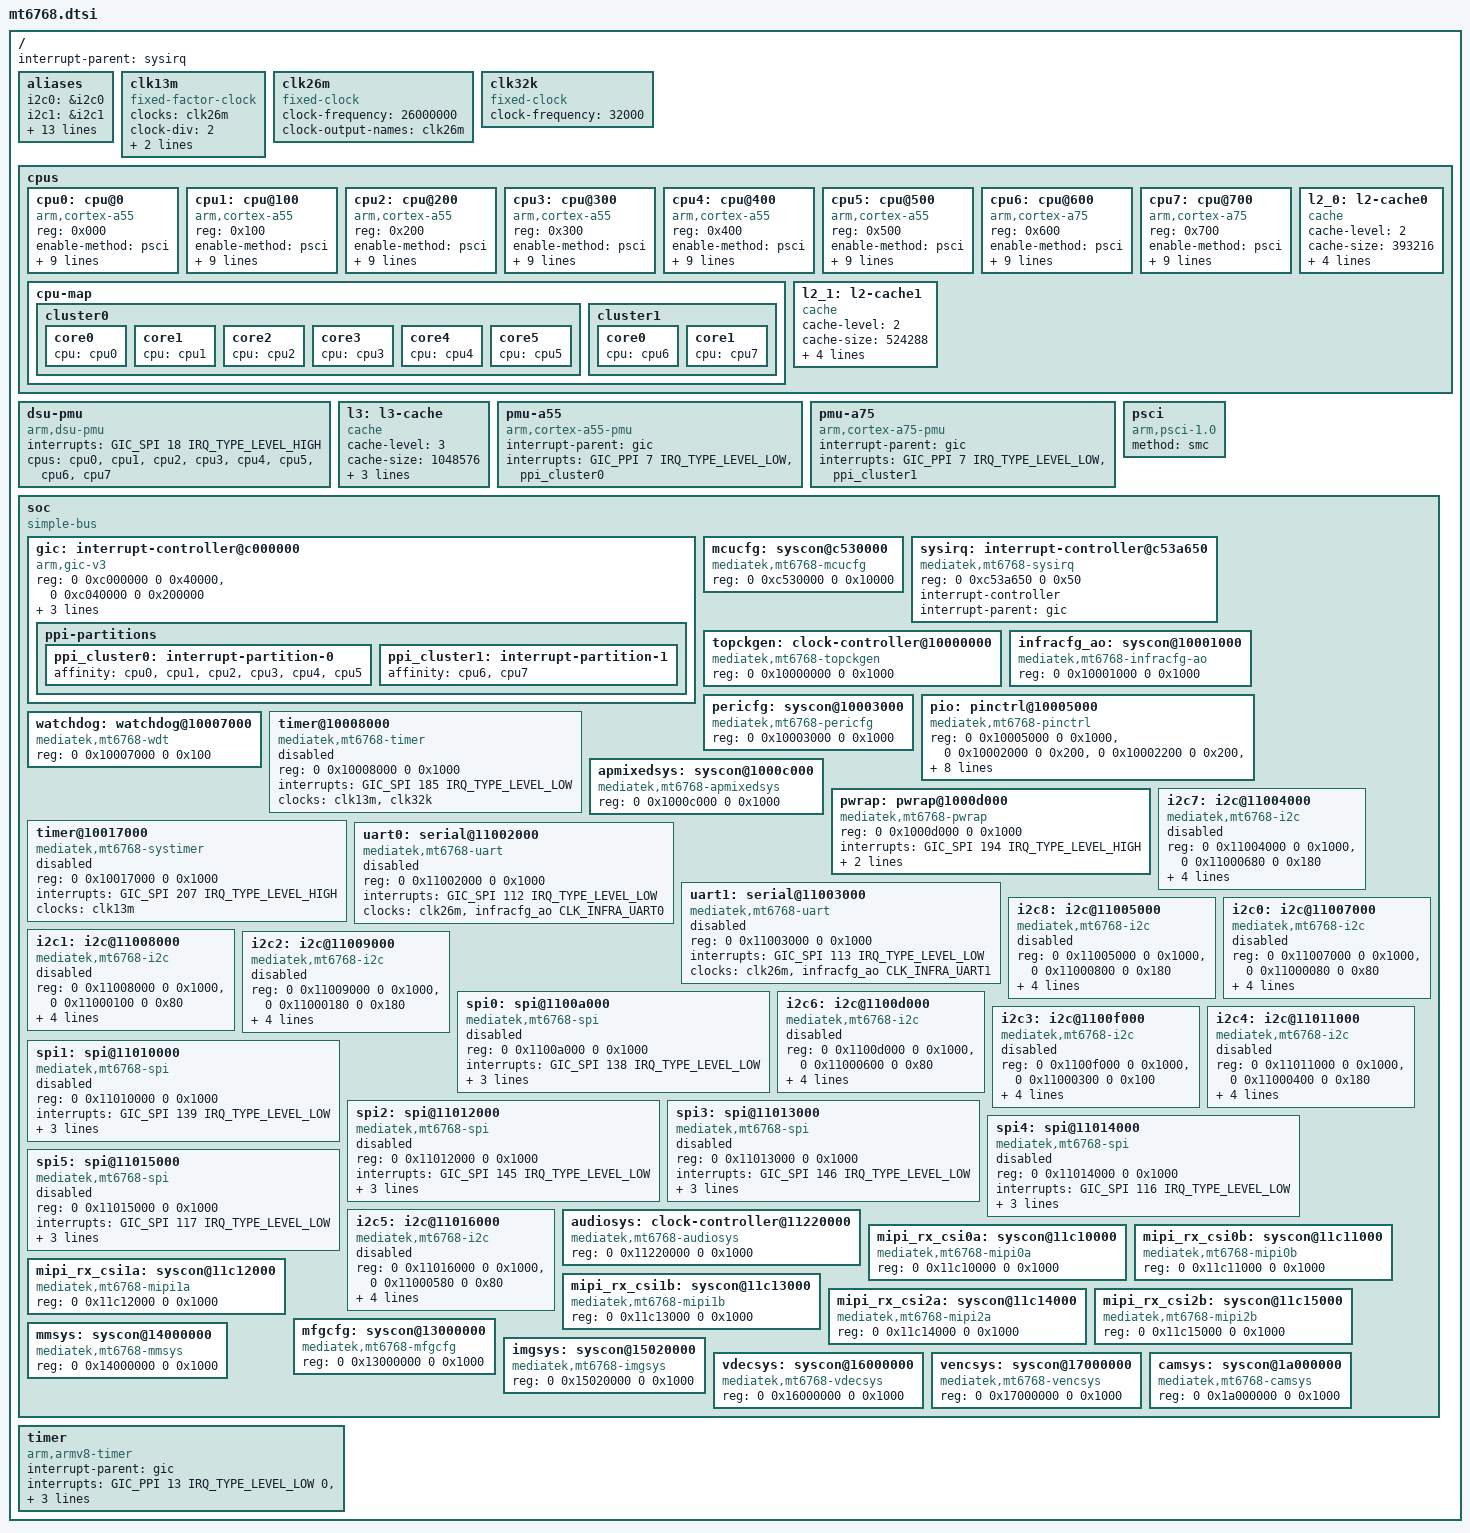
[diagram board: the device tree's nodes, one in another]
// SPDX-License-Identifier: GPL-2.0+
/*
 * Copyright (c) 2025-2026 Roman Vivchar <rva333@protonmail.com>
 */

#include <dt-bindings/interrupt-controller/arm-gic.h>
#include <dt-bindings/interrupt-controller/irq.h>
#include <dt-bindings/clock/mediatek,mt6768-clock.h>
#include <dt-bindings/pinctrl/mediatek,mt6768-pinfunc.h>
#include <dt-bindings/reset/mediatek,mt6768-resets.h>

/ {
	interrupt-parent = <&sysirq>;
	#address-cells = <2>;
	#size-cells = <2>;

	aliases {
		i2c0 = &i2c0;
		i2c1 = &i2c1;
		i2c2 = &i2c2;
		i2c3 = &i2c3;
		i2c4 = &i2c4;
		i2c5 = &i2c5;
		i2c6 = &i2c6;
		i2c7 = &i2c7;
		i2c8 = &i2c8;
		spi0 = &spi0;
		spi1 = &spi1;
		spi2 = &spi2;
		spi3 = &spi3;
		spi4 = &spi4;
		spi5 = &spi5;
	};

	clk13m: clk13m {
		compatible = "fixed-factor-clock";
		#clock-cells = <0>;
		clocks = <&clk26m>;
		clock-div = <2>;
		clock-mult = <1>;
		clock-output-names = "clk13m";
	};

	clk26m: clk26m {
		compatible = "fixed-clock";
		#clock-cells = <0>;
		clock-frequency = <26000000>;
		clock-output-names = "clk26m";
	};

	clk32k: clk32k {
		compatible = "fixed-clock";
		#clock-cells = <0>;
		clock-frequency = <32000>;
	};

	cpus {
		#address-cells = <1>;
		#size-cells = <0>;

		cpu0: cpu@0 {
			device_type = "cpu";
			compatible = "arm,cortex-a55";
			reg = <0x000>;
			enable-method = "psci";
			dynamic-power-coefficient = <85>;
			capacity-dmips-mhz = <495>;
			i-cache-size = <32768>;
			i-cache-line-size = <64>;
			i-cache-sets = <256>;
			d-cache-size = <32768>;
			d-cache-line-size = <64>;
			d-cache-sets = <128>;
			next-level-cache = <&l2_0>;
			#cooling-cells = <2>;
		};

		cpu1: cpu@100 {
			device_type = "cpu";
			compatible = "arm,cortex-a55";
			reg = <0x100>;
			enable-method = "psci";
			dynamic-power-coefficient = <85>;
			capacity-dmips-mhz = <495>;
			i-cache-size = <32768>;
			i-cache-line-size = <64>;
			i-cache-sets = <256>;
			d-cache-size = <32768>;
			d-cache-line-size = <64>;
			d-cache-sets = <128>;
			next-level-cache = <&l2_0>;
			#cooling-cells = <2>;
		};

		cpu2: cpu@200 {
			device_type = "cpu";
			compatible = "arm,cortex-a55";
			reg = <0x200>;
			enable-method = "psci";
			dynamic-power-coefficient = <85>;
			capacity-dmips-mhz = <495>;
			i-cache-size = <32768>;
			i-cache-line-size = <64>;
			i-cache-sets = <256>;
			d-cache-size = <32768>;
			d-cache-line-size = <64>;
			d-cache-sets = <128>;
			next-level-cache = <&l2_0>;
			#cooling-cells = <2>;
		};

		cpu3: cpu@300 {
			device_type = "cpu";
			compatible = "arm,cortex-a55";
			reg = <0x300>;
			enable-method = "psci";
			dynamic-power-coefficient = <85>;
			capacity-dmips-mhz = <495>;
			i-cache-size = <32768>;
			i-cache-line-size = <64>;
			i-cache-sets = <256>;
			d-cache-size = <32768>;
			d-cache-line-size = <64>;
			d-cache-sets = <128>;
			next-level-cache = <&l2_0>;
			#cooling-cells = <2>;
		};

		cpu4: cpu@400 {
			device_type = "cpu";
			compatible = "arm,cortex-a55";
			reg = <0x400>;
			enable-method = "psci";
			dynamic-power-coefficient = <85>;
			capacity-dmips-mhz = <495>;
			i-cache-size = <32768>;
			i-cache-line-size = <64>;
			i-cache-sets = <256>;
			d-cache-size = <32768>;
			d-cache-line-size = <64>;
			d-cache-sets = <128>;
			next-level-cache = <&l2_0>;
			#cooling-cells = <2>;
		};

		cpu5: cpu@500 {
			device_type = "cpu";
			compatible = "arm,cortex-a55";
			reg = <0x500>;
			enable-method = "psci";
			dynamic-power-coefficient = <85>;
			capacity-dmips-mhz = <495>;
			i-cache-size = <32768>;
			i-cache-line-size = <64>;
			i-cache-sets = <256>;
			d-cache-size = <32768>;
			d-cache-line-size = <64>;
			d-cache-sets = <128>;
			next-level-cache = <&l2_0>;
			#cooling-cells = <2>;
		};

		cpu6: cpu@600 {
			device_type = "cpu";
			compatible = "arm,cortex-a75";
			reg = <0x600>;
			enable-method = "psci";
			dynamic-power-coefficient = <275>;
			capacity-dmips-mhz = <1024>;
			i-cache-size = <65536>;
			i-cache-line-size = <64>;
			i-cache-sets = <256>;
			d-cache-size = <65536>;
			d-cache-line-size = <64>;
			d-cache-sets = <256>;
			next-level-cache = <&l2_1>;
			#cooling-cells = <2>;
		};

		cpu7: cpu@700 {
			device_type = "cpu";
			compatible = "arm,cortex-a75";
			reg = <0x700>;
			enable-method = "psci";
			dynamic-power-coefficient = <275>;
			capacity-dmips-mhz = <1024>;
			i-cache-size = <65536>;
			i-cache-line-size = <64>;
			i-cache-sets = <256>;
			d-cache-size = <65536>;
			d-cache-line-size = <64>;
			d-cache-sets = <256>;
			next-level-cache = <&l2_1>;
			#cooling-cells = <2>;
		};

		cpu-map {
			cluster0 {
				core0 {
					cpu = <&cpu0>;
				};

				core1 {
					cpu = <&cpu1>;
				};

				core2 {
					cpu = <&cpu2>;
				};

				core3 {
					cpu = <&cpu3>;
				};

				core4 {
					cpu = <&cpu4>;
				};

				core5 {
					cpu = <&cpu5>;
				};
			};

			cluster1 {
				core0 {
					cpu = <&cpu6>;
				};

				core1 {
					cpu = <&cpu7>;
				};
			};
		};

		l2_0: l2-cache0 {
			compatible = "cache";
			cache-level = <2>;
			cache-size = <393216>; // 64K x 6
			cache-line-size = <64>;
			cache-sets = <512>; // I guess
			next-level-cache = <&l3>;
			cache-unified;
		};

		l2_1: l2-cache1 {
			compatible = "cache";
			cache-level = <2>;
			cache-size = <524288>; // 256K x 2
			cache-line-size = <64>;
			cache-sets = <512>;
			next-level-cache = <&l3>;
			cache-unified;
		};
	};

	dsu-pmu {
		compatible = "arm,dsu-pmu";
		interrupts = <GIC_SPI 18 IRQ_TYPE_LEVEL_HIGH>;
		cpus = <&cpu0>, <&cpu1>, <&cpu2>, <&cpu3>,
		       <&cpu4>, <&cpu5>, <&cpu6>, <&cpu7>;
	};

	l3: l3-cache {
		compatible = "cache";
		cache-level = <3>;
		cache-size = <1048576>;
		cache-line-size = <64>;
		cache-sets = <1024>;
		cache-unified;
	};

	pmu-a55 {
		compatible = "arm,cortex-a55-pmu";
		interrupt-parent = <&gic>;
		interrupts = <GIC_PPI 7 IRQ_TYPE_LEVEL_LOW &ppi_cluster0>;
	};

	pmu-a75 {
		compatible = "arm,cortex-a75-pmu";
		interrupt-parent = <&gic>;
		interrupts = <GIC_PPI 7 IRQ_TYPE_LEVEL_LOW &ppi_cluster1>;
	};

	psci {
		compatible = "arm,psci-1.0";
		method = "smc";
	};

	soc {
		compatible = "simple-bus";
		ranges;
		#address-cells = <2>;
		#size-cells = <2>;

		gic: interrupt-controller@c000000 {
			compatible = "arm,gic-v3";
			reg = <0 0xc000000 0 0x40000>,
			      <0 0xc040000 0 0x200000>;
			#interrupt-cells = <4>;
			interrupt-parent = <&gic>;
			interrupt-controller;

			interrupts = <GIC_PPI 9 IRQ_TYPE_LEVEL_HIGH 0>;

			ppi-partitions {
				ppi_cluster0: interrupt-partition-0 {
					affinity = <&cpu0 &cpu1 &cpu2 &cpu3 &cpu4 &cpu5>;
				};

				ppi_cluster1: interrupt-partition-1 {
					affinity = <&cpu6 &cpu7>;
				};
			};
		};

		mcucfg: syscon@c530000 {
			compatible = "mediatek,mt6768-mcucfg", "syscon";
			reg = <0 0xc530000 0 0x10000>;
			#clock-cells = <1>;
		};

		sysirq: interrupt-controller@c53a650 {
			compatible = "mediatek,mt6768-sysirq", "mediatek,mt6577-sysirq";
			reg = <0 0xc53a650 0 0x50>;
			interrupt-controller;
			#interrupt-cells = <3>;
			interrupt-parent = <&gic>;
		};

		topckgen: clock-controller@10000000 {
			compatible = "mediatek,mt6768-topckgen", "syscon";
			reg = <0 0x10000000 0 0x1000>;
			#clock-cells = <1>;
		};

		infracfg_ao: syscon@10001000 {
			compatible = "mediatek,mt6768-infracfg-ao", "syscon";
			reg = <0 0x10001000 0 0x1000>;
			#clock-cells = <1>;
			#reset-cells = <1>;
		};

		pericfg: syscon@10003000 {
			compatible = "mediatek,mt6768-pericfg", "syscon";
			reg = <0 0x10003000 0 0x1000>;
		};

		pio: pinctrl@10005000 {
			compatible = "mediatek,mt6768-pinctrl";
			reg = <0 0x10005000 0 0x1000>,
			      <0 0x10002000 0 0x200>,
			      <0 0x10002200 0 0x200>,
			      <0 0x10002400 0 0x200>,
			      <0 0x10002600 0 0x200>,
			      <0 0x10002800 0 0x200>,
			      <0 0x10002a00 0 0x200>,
			      <0 0x10002c00 0 0x200>,
			      <0 0x10002e00 0 0x200>,
			      <0 0x1000b000 0 0x1000>;
			reg-names = "gpio", "iocfg_lt", "iocfg_lm", "iocfg_lb",
				    "iocfg_bl", "iocfg_rm", "iocfg_rb", "iocfg_rt",
				    "iocfg_tl", "eint";
			gpio-controller;
			#gpio-cells = <2>;
			gpio-ranges = <&pio 0 0 187>;
			interrupt-controller;
			interrupts = <GIC_SPI 186 IRQ_TYPE_LEVEL_HIGH>;
			#interrupt-cells = <2>;
		};

		watchdog: watchdog@10007000 {
			compatible = "mediatek,mt6768-wdt";
			reg = <0 0x10007000 0 0x100>;
			#reset-cells = <1>;
		};

		timer@10008000 {
			compatible = "mediatek,mt6768-timer",
				     "mediatek,mt6577-timer";
			reg = <0 0x10008000 0 0x1000>;
			interrupts = <GIC_SPI 185 IRQ_TYPE_LEVEL_LOW>;
			clocks = <&clk13m>, <&clk32k>;

			status = "disabled";
		};

		apmixedsys: syscon@1000c000 {
			compatible = "mediatek,mt6768-apmixedsys", "syscon";
			reg = <0 0x1000c000 0 0x1000>;
			#clock-cells = <1>;
		};

		pwrap: pwrap@1000d000 {
			compatible = "mediatek,mt6768-pwrap";
			reg = <0 0x1000d000 0 0x1000>;
			reg-names = "pwrap";
			interrupts = <GIC_SPI 194 IRQ_TYPE_LEVEL_HIGH>;
			clocks = <&infracfg_ao CLK_INFRA_PMIC_AP>,
				 <&infracfg_ao CLK_INFRA_PMIC_TMR>;
			clock-names = "spi", "wrap";
		};

		timer@10017000 {
			compatible = "mediatek,mt6768-systimer",
				     "mediatek,mt6765-timer";
			reg = <0 0x10017000 0 0x1000>;
			interrupts = <GIC_SPI 207 IRQ_TYPE_LEVEL_HIGH>;
			clocks = <&clk13m>;

			status = "disabled";
		};

		uart0: serial@11002000 {
			compatible = "mediatek,mt6768-uart", "mediatek,mt6577-uart";
			reg = <0 0x11002000 0 0x1000>;
			interrupts = <GIC_SPI 112 IRQ_TYPE_LEVEL_LOW>;
			clocks = <&clk26m>, <&infracfg_ao CLK_INFRA_UART0>;
			clock-names = "baud", "bus";

			status = "disabled";
		};

		uart1: serial@11003000 {
			compatible = "mediatek,mt6768-uart", "mediatek,mt6577-uart";
			reg = <0 0x11003000 0 0x1000>;
			interrupts = <GIC_SPI 113 IRQ_TYPE_LEVEL_LOW>;
			clocks = <&clk26m>, <&infracfg_ao CLK_INFRA_UART1>;
			clock-names = "baud", "bus";

			status = "disabled";
		};

		i2c7: i2c@11004000 {
			compatible = "mediatek,mt6768-i2c";
			reg = <0 0x11004000 0 0x1000>,
			      <0 0x11000680 0 0x180>;
			interrupts = <GIC_SPI 110 IRQ_TYPE_LEVEL_LOW>;
			clocks = <&infracfg_ao CLK_INFRA_I2C_AP>,
				 <&infracfg_ao CLK_INFRA_AP_DMA>;
			clock-names = "main", "dma";
			clock-div = <1>;
			#address-cells = <1>;
			#size-cells = <0>;

			status = "disabled";
		};

		i2c8: i2c@11005000 {
			compatible = "mediatek,mt6768-i2c";
			reg = <0 0x11005000 0 0x1000>,
			      <0 0x11000800 0 0x180>;
			interrupts = <GIC_SPI 111 IRQ_TYPE_LEVEL_LOW>;
			clocks = <&infracfg_ao CLK_INFRA_I2C_AP>,
				 <&infracfg_ao CLK_INFRA_AP_DMA>;
			clock-names = "main", "dma";
			clock-div = <1>;
			#address-cells = <1>;
			#size-cells = <0>;

			status = "disabled";
		};

		i2c0: i2c@11007000 {
			compatible = "mediatek,mt6768-i2c";
			reg = <0 0x11007000 0 0x1000>,
			      <0 0x11000080 0 0x80>;
			interrupts = <GIC_SPI 105 IRQ_TYPE_LEVEL_LOW>;
			clocks = <&infracfg_ao CLK_INFRA_I2C_AP>,
				 <&infracfg_ao CLK_INFRA_AP_DMA>;
			clock-names = "main", "dma";
			clock-div = <1>;
			#address-cells = <1>;
			#size-cells = <0>;

			status = "disabled";
		};

		i2c1: i2c@11008000 {
			compatible = "mediatek,mt6768-i2c";
			reg = <0 0x11008000 0 0x1000>,
			      <0 0x11000100 0 0x80>;
			interrupts = <GIC_SPI 106 IRQ_TYPE_LEVEL_LOW>;
			clocks = <&infracfg_ao CLK_INFRA_I2C_AP>,
				 <&infracfg_ao CLK_INFRA_AP_DMA>;
			clock-names = "main", "dma";
			clock-div = <1>;
			#address-cells = <1>;
			#size-cells = <0>;

			status = "disabled";
		};

		i2c2: i2c@11009000 {
			compatible = "mediatek,mt6768-i2c";
			reg = <0 0x11009000 0 0x1000>,
			      <0 0x11000180 0 0x180>;
			interrupts = <GIC_SPI 107 IRQ_TYPE_LEVEL_LOW>;
			clocks = <&infracfg_ao CLK_INFRA_I2C_AP>,
				 <&infracfg_ao CLK_INFRA_AP_DMA>;
			clock-names = "main", "dma";
			clock-div = <1>;
			#address-cells = <1>;
			#size-cells = <0>;

			status = "disabled";
		};

		spi0: spi@1100a000 {
			compatible = "mediatek,mt6768-spi", "mediatek,mt6765-spi";
			reg = <0 0x1100a000 0 0x1000>;
			#address-cells = <1>;
			#size-cells = <0>;
			interrupts = <GIC_SPI 138 IRQ_TYPE_LEVEL_LOW>;
			clocks = <&topckgen CLK_TOP_SYSPLL3_D2>,
				 <&topckgen CLK_TOP_SPI_SEL>,
				 <&infracfg_ao CLK_INFRA_SPI0>;
			clock-names = "parent-clk", "sel-clk", "spi-clk";

			status = "disabled";
		};

		i2c6: i2c@1100d000 {
			compatible = "mediatek,mt6768-i2c";
			reg = <0 0x1100d000 0 0x1000>,
			      <0 0x11000600 0 0x80>;
			interrupts = <GIC_SPI 148 IRQ_TYPE_LEVEL_LOW>;
			clocks = <&infracfg_ao CLK_INFRA_I2C_AP>,
				 <&infracfg_ao CLK_INFRA_AP_DMA>;
			clock-names = "main", "dma";
			clock-div = <1>;
			#address-cells = <1>;
			#size-cells = <0>;

			status = "disabled";
		};

		i2c3: i2c@1100f000 {
			compatible = "mediatek,mt6768-i2c";
			reg = <0 0x1100f000 0 0x1000>,
			      <0 0x11000300 0 0x100>;
			interrupts = <GIC_SPI 108 IRQ_TYPE_LEVEL_LOW>;
			clocks = <&infracfg_ao CLK_INFRA_I2C_AP>,
				 <&infracfg_ao CLK_INFRA_AP_DMA>;
			clock-names = "main", "dma";
			clock-div = <1>;
			#address-cells = <1>;
			#size-cells = <0>;

			status = "disabled";
		};

		spi1: spi@11010000 {
			compatible = "mediatek,mt6768-spi", "mediatek,mt6765-spi";
			reg = <0 0x11010000 0 0x1000>;
			#address-cells = <1>;
			#size-cells = <0>;
			interrupts = <GIC_SPI 139 IRQ_TYPE_LEVEL_LOW>;
			clocks = <&topckgen CLK_TOP_SYSPLL3_D2>,
				 <&topckgen CLK_TOP_SPI_SEL>,
				 <&infracfg_ao CLK_INFRA_SPI1>;
			clock-names = "parent-clk", "sel-clk", "spi-clk";

			status = "disabled";
		};

		i2c4: i2c@11011000 {
			compatible = "mediatek,mt6768-i2c";
			reg = <0 0x11011000 0 0x1000>,
			      <0 0x11000400 0 0x180>;
			interrupts = <GIC_SPI 109 IRQ_TYPE_LEVEL_LOW>;
			clocks = <&infracfg_ao CLK_INFRA_I2C_AP>,
				 <&infracfg_ao CLK_INFRA_AP_DMA>;
			clock-names = "main", "dma";
			clock-div = <1>;
			#address-cells = <1>;
			#size-cells = <0>;

			status = "disabled";
		};

		spi2: spi@11012000 {
			compatible = "mediatek,mt6768-spi", "mediatek,mt6765-spi";
			reg = <0 0x11012000 0 0x1000>;
			#address-cells = <1>;
			#size-cells = <0>;
			interrupts = <GIC_SPI 145 IRQ_TYPE_LEVEL_LOW>;
			clocks = <&topckgen CLK_TOP_SYSPLL3_D2>,
				 <&topckgen CLK_TOP_SPI_SEL>,
				 <&infracfg_ao CLK_INFRA_SPI2>;
			clock-names = "parent-clk", "sel-clk", "spi-clk";

			status = "disabled";
		};

		spi3: spi@11013000 {
			compatible = "mediatek,mt6768-spi", "mediatek,mt6765-spi";
			reg = <0 0x11013000 0 0x1000>;
			#address-cells = <1>;
			#size-cells = <0>;
			interrupts = <GIC_SPI 146 IRQ_TYPE_LEVEL_LOW>;
			clocks = <&topckgen CLK_TOP_SYSPLL3_D2>,
				 <&topckgen CLK_TOP_SPI_SEL>,
				 <&infracfg_ao CLK_INFRA_SPI3>;
			clock-names = "parent-clk", "sel-clk", "spi-clk";

			status = "disabled";
		};

		spi4: spi@11014000 {
			compatible = "mediatek,mt6768-spi", "mediatek,mt6765-spi";
			reg = <0 0x11014000 0 0x1000>;
			#address-cells = <1>;
			#size-cells = <0>;
			interrupts = <GIC_SPI 116 IRQ_TYPE_LEVEL_LOW>;
			clocks = <&topckgen CLK_TOP_SYSPLL3_D2>,
				 <&topckgen CLK_TOP_SPI_SEL>,
				 <&infracfg_ao CLK_INFRA_SPI4>;
			clock-names = "parent-clk", "sel-clk", "spi-clk";

			status = "disabled";
		};

		spi5: spi@11015000 {
			compatible = "mediatek,mt6768-spi", "mediatek,mt6765-spi";
			reg = <0 0x11015000 0 0x1000>;
			#address-cells = <1>;
			#size-cells = <0>;
			interrupts = <GIC_SPI 117 IRQ_TYPE_LEVEL_LOW>;
			clocks = <&topckgen CLK_TOP_SYSPLL3_D2>,
				 <&topckgen CLK_TOP_SPI_SEL>,
				 <&infracfg_ao CLK_INFRA_SPI5>;
			clock-names = "parent-clk", "sel-clk", "spi-clk";

			status = "disabled";
		};

		i2c5: i2c@11016000 {
			compatible = "mediatek,mt6768-i2c";
			reg = <0 0x11016000 0 0x1000>,
			      <0 0x11000580 0 0x80>;
			interrupts = <GIC_SPI 147 IRQ_TYPE_LEVEL_LOW>;
			clocks = <&infracfg_ao CLK_INFRA_I2C_AP>,
				 <&infracfg_ao CLK_INFRA_AP_DMA>;
			clock-names = "main", "dma";
			clock-div = <1>;
			#address-cells = <1>;
			#size-cells = <0>;

			status = "disabled";
		};

		audiosys: clock-controller@11220000 {
			compatible = "mediatek,mt6768-audiosys", "syscon";
			reg = <0 0x11220000 0 0x1000>;
			#clock-cells = <1>;
		};

		mipi_rx_csi0a: syscon@11c10000 {
			compatible = "mediatek,mt6768-mipi0a", "syscon";
			reg = <0 0x11c10000 0 0x1000>;
			#clock-cells = <1>;
		};

		mipi_rx_csi0b: syscon@11c11000 {
			compatible = "mediatek,mt6768-mipi0b", "syscon";
			reg = <0 0x11c11000 0 0x1000>;
			#clock-cells = <1>;
		};

		mipi_rx_csi1a: syscon@11c12000 {
			compatible = "mediatek,mt6768-mipi1a", "syscon";
			reg = <0 0x11c12000 0 0x1000>;
			#clock-cells = <1>;
		};

		mipi_rx_csi1b: syscon@11c13000 {
			compatible = "mediatek,mt6768-mipi1b", "syscon";
			reg = <0 0x11c13000 0 0x1000>;
			#clock-cells = <1>;
		};

		mipi_rx_csi2a: syscon@11c14000 {
			compatible = "mediatek,mt6768-mipi2a", "syscon";
			reg = <0 0x11c14000 0 0x1000>;
			#clock-cells = <1>;
		};

		mipi_rx_csi2b: syscon@11c15000 {
			compatible = "mediatek,mt6768-mipi2b", "syscon";
			reg = <0 0x11c15000 0 0x1000>;
			#clock-cells = <1>;
		};

		mfgcfg: syscon@13000000 {
			compatible = "mediatek,mt6768-mfgcfg", "mediatek,mt8183-mfgcfg",
				     "syscon";
			reg = <0 0x13000000 0 0x1000>;
			#clock-cells = <1>;
		};

		mmsys: syscon@14000000 {
			compatible = "mediatek,mt6768-mmsys", "syscon";
			reg = <0 0x14000000 0 0x1000>;
			#clock-cells = <1>;
			#reset-cells = <1>;
		};

		imgsys: syscon@15020000 {
			compatible = "mediatek,mt6768-imgsys", "syscon";
			reg = <0 0x15020000 0 0x1000>;
			#clock-cells = <1>;
		};

		vdecsys: syscon@16000000 {
			compatible = "mediatek,mt6768-vdecsys", "syscon";
			reg = <0 0x16000000 0 0x1000>;
			#clock-cells = <1>;
		};

		vencsys: syscon@17000000 {
			compatible = "mediatek,mt6768-vencsys",
				     "mediatek,mt8183-vencsys", "syscon";
			reg = <0 0x17000000 0 0x1000>;
			#clock-cells = <1>;
		};

		camsys: syscon@1a000000 {
			compatible = "mediatek,mt6768-camsys", "syscon";
			reg = <0 0x1a000000 0 0x1000>;
			#clock-cells = <1>;
		};
	};

	timer {
		compatible = "arm,armv8-timer";
		interrupt-parent = <&gic>;
		interrupts = <GIC_PPI 13 IRQ_TYPE_LEVEL_LOW 0>,
			     <GIC_PPI 14 IRQ_TYPE_LEVEL_LOW 0>,
			     <GIC_PPI 11 IRQ_TYPE_LEVEL_LOW 0>,
			     <GIC_PPI 10 IRQ_TYPE_LEVEL_LOW 0>;
	};
};
